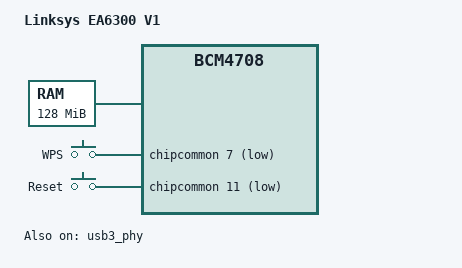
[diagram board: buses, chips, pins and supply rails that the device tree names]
// SPDX-License-Identifier: GPL-2.0-or-later OR MIT
/*
 * Copyright (C) 2017 Rafał Miłecki <rafal@milecki.pl>
 */

/dts-v1/;

#include "bcm4708.dtsi"
#include "bcm5301x-nand-cs0-bch8.dtsi"

/ {
	compatible = "linksys,ea6300-v1", "brcm,bcm4708";
	model = "Linksys EA6300 V1";

	chosen {
		bootargs = "console=ttyS0,115200";
	};

	memory {
		reg = <0x00000000 0x08000000>;
	};

	gpio-keys {
		compatible = "gpio-keys";
		#address-cells = <1>;
		#size-cells = <0>;

		wps {
			label = "WPS";
			linux,code = <KEY_WPS_BUTTON>;
			gpios = <&chipcommon 7 GPIO_ACTIVE_LOW>;
		};

		restart {
			label = "Reset";
			linux,code = <KEY_RESTART>;
			gpios = <&chipcommon 11 GPIO_ACTIVE_LOW>;
		};
	};
};

&usb3_phy {
	status = "okay";
};
